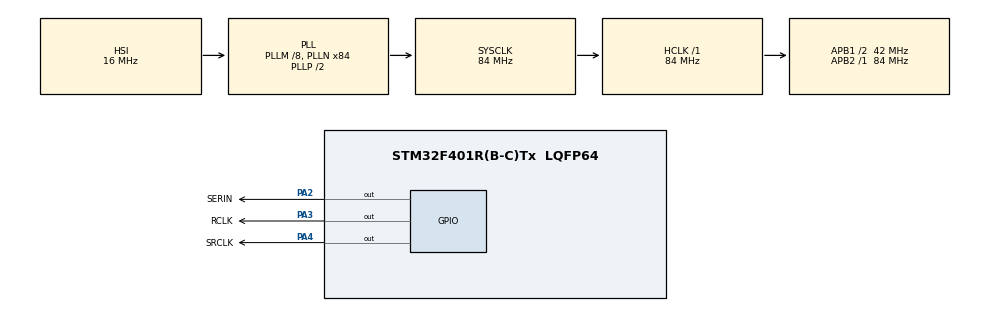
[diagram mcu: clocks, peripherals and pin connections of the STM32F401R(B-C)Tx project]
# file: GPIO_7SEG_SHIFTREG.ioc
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Mcu.Family=STM32F4
Mcu.Name=STM32F401R(B-C)Tx
Mcu.Package=LQFP64
NVIC.PriorityGroup=NVIC_PRIORITYGROUP_4
PA2.GPIO_Label=SERIN
PA2.Signal=GPIO_Output
PA3.GPIO_Label=RCLK
PA3.Signal=GPIO_Output
PA4.GPIO_Label=SRCLK
PA4.Signal=GPIO_Output
ProjectManager.HeapSize=0x200
ProjectManager.StackSize=0x400
ProjectManager.TargetToolchain=STM32CubeIDE
RCC.48MHZClocksFreq_Value=42000000
RCC.AHBFreq_Value=84000000
RCC.APB1CLKDivider=RCC_HCLK_DIV2
RCC.APB1Freq_Value=42000000
RCC.APB1TimFreq_Value=84000000
RCC.APB2Freq_Value=84000000
RCC.APB2TimFreq_Value=84000000
RCC.CortexFreq_Value=84000000
RCC.HCLKFreq_Value=84000000
RCC.HSE_VALUE=25000000
RCC.HSI_VALUE=16000000
RCC.LSE_VALUE=32768
RCC.PLLM=8
RCC.PLLN=84
RCC.SYSCLKFreq_VALUE=84000000
RCC.SYSCLKSource=RCC_SYSCLKSOURCE_PLLCLK
RCC.VCOOutputFreq_Value=168000000
board=custom

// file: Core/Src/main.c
/* USER CODE BEGIN Header */
/**
  ******************************************************************************
  * @file           : main.c
  * @brief          : Main program body
  ******************************************************************************
  * @attention
  *
  * Copyright (c) 2024 STMicroelectronics.
  * All rights reserved.
  *
  * This software is licensed under terms that can be found in the LICENSE file
  * in the root directory of this software component.
  * If no LICENSE file comes with this software, it is provided AS-IS.
  *
  ******************************************************************************
  */
/* USER CODE END Header */
#include "main.h"
#include "gpio.h"

void SystemClock_Config(void);
/* USER CODE BEGIN PFP */
void PulsePin(GPIO_TypeDef *port, uint16_t pin);
void ShiftRegister_WriteByte(uint8_t data);
/* USER CODE END PFP */

int main(void)
{

  /* MCU Configuration--------------------------------------------------------*/

  /* Reset of all peripherals, Initializes the Flash interface and the Systick. */
  HAL_Init();

  /* Configure the system clock */
  SystemClock_Config();

  /* Initialize all configured peripherals */
  MX_GPIO_Init();

  /* Infinite loop */
  /* USER CODE BEGIN WHILE */
  while (1)
  {

	  for(uint8_t data = 0x80, i =0;i<8;i++)
	  {
		  ShiftRegister_WriteByte(~(data>>i));
		  HAL_Delay(500);
	  }
    /* USER CODE END WHILE */

  }
}

void SystemClock_Config(void)
{
  RCC_OscInitTypeDef RCC_OscInitStruct = {0};
  RCC_ClkInitTypeDef RCC_ClkInitStruct = {0};

  /** Configure the main internal regulator output voltage
  */
  __HAL_RCC_PWR_CLK_ENABLE();
  __HAL_PWR_VOLTAGESCALING_CONFIG(PWR_REGULATOR_VOLTAGE_SCALE2);

  /** Initializes the RCC Oscillators according to the specified parameters
  * in the RCC_OscInitTypeDef structure.
  */
  RCC_OscInitStruct.OscillatorType = RCC_OSCILLATORTYPE_HSI;
  RCC_OscInitStruct.HSIState = RCC_HSI_ON;
  RCC_OscInitStruct.HSICalibrationValue = RCC_HSICALIBRATION_DEFAULT;
  RCC_OscInitStruct.PLL.PLLState = RCC_PLL_ON;
  RCC_OscInitStruct.PLL.PLLSource = RCC_PLLSOURCE_HSI;
  RCC_OscInitStruct.PLL.PLLM = 8;
  RCC_OscInitStruct.PLL.PLLN = 84;
  RCC_OscInitStruct.PLL.PLLP = RCC_PLLP_DIV2;
  RCC_OscInitStruct.PLL.PLLQ = 4;
  if (HAL_RCC_OscConfig(&RCC_OscInitStruct) != HAL_OK)
  {
    Error_Handler();
  }

  /** Initializes the CPU, AHB and APB buses clocks
  */
  RCC_ClkInitStruct.ClockType = RCC_CLOCKTYPE_HCLK|RCC_CLOCKTYPE_SYSCLK
                              |RCC_CLOCKTYPE_PCLK1|RCC_CLOCKTYPE_PCLK2;
  RCC_ClkInitStruct.SYSCLKSource = RCC_SYSCLKSOURCE_PLLCLK;
  RCC_ClkInitStruct.AHBCLKDivider = RCC_SYSCLK_DIV1;
  RCC_ClkInitStruct.APB1CLKDivider = RCC_HCLK_DIV2;
  RCC_ClkInitStruct.APB2CLKDivider = RCC_HCLK_DIV1;

  if (HAL_RCC_ClockConfig(&RCC_ClkInitStruct, FLASH_LATENCY_2) != HAL_OK)
  {
    Error_Handler();
  }
}

/* USER CODE BEGIN 4 */

void ShiftRegister_WriteByte(uint8_t data)
{
    for (int i = 0; i < 8; i++) {
        // Write the bit to SERIN
        if (data & 0x80) {
            HAL_GPIO_WritePin(SERIN_GPIO_Port, SERIN_Pin, GPIO_PIN_SET);  // Send 1
        } else {
            HAL_GPIO_WritePin(SERIN_GPIO_Port, SERIN_Pin, GPIO_PIN_RESET);  // Send 0
        }
        data <<= 1;

        // Pulse the SRCLK (Shift Clock)
        PulsePin(SRCLK_GPIO_Port, SRCLK_Pin);
    }

    // Pulse the RCLK (Latch Clock) to output data to the parallel pins
    PulsePin(RCLK_GPIO_Port, RCLK_Pin);
}

void PulsePin(GPIO_TypeDef *port, uint16_t pin)
{
    HAL_GPIO_WritePin(port, pin, GPIO_PIN_SET);
    HAL_Delay(1);  // Short delay
    HAL_GPIO_WritePin(port, pin, GPIO_PIN_RESET);
}
/* USER CODE END 4 */

void Error_Handler(void)
{
  __disable_irq();
  while (1)
  {
  }
}
